# N32MC47x_DP47x register map
Vendor: Nsingtech Ltd.; File version: 1.0
Registers are 32-bit, read-write, reset 0x0 unless marked. A register's access mark holds for its fields unless they carry their own. Offsets are from the block's base; [hi:lo] are bit positions; {n}, {i} and the like mark numbered series; 'fields as' and 'values as' point back to an identical list.

## DAC56
Base 0x4002A800
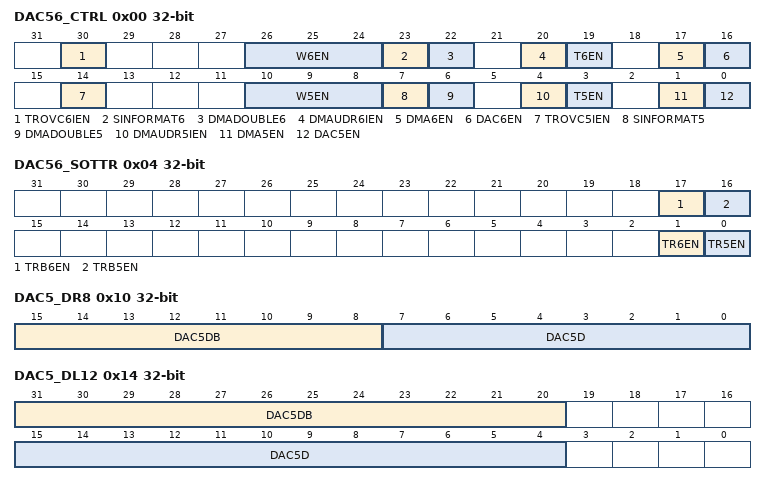
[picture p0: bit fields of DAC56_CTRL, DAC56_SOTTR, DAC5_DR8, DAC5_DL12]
0x00 DAC56_CTRL
  [30] TROVC6IEN, [26:24] W6EN, [23] SINFORMAT6, [22] DMADOUBLE6, [20] DMAUDR6IEN, [19] T6EN, [17] DMA6EN, [16] DAC6EN, [14] TROVC5IEN, [10:8] W5EN, [7] SINFORMAT5, [6] DMADOUBLE5, [4] DMAUDR5IEN, [3] T5EN, [1] DMA5EN, [0] DAC5EN
0x04 DAC56_SOTTR
  [17] TRB6EN, [16] TRB5EN, [1] TR6EN, [0] TR5EN
0x08 DAC5_DATO
  [11:0] DAC5DO
0x0C DAC6_DATO
  [11:0] DAC6DO
0x10 DAC5_DR8
  [15:8] DAC5DB, [7:0] DAC5D
0x14 DAC5_DL12
  [31:20] DAC5DB, [15:4] DAC5D
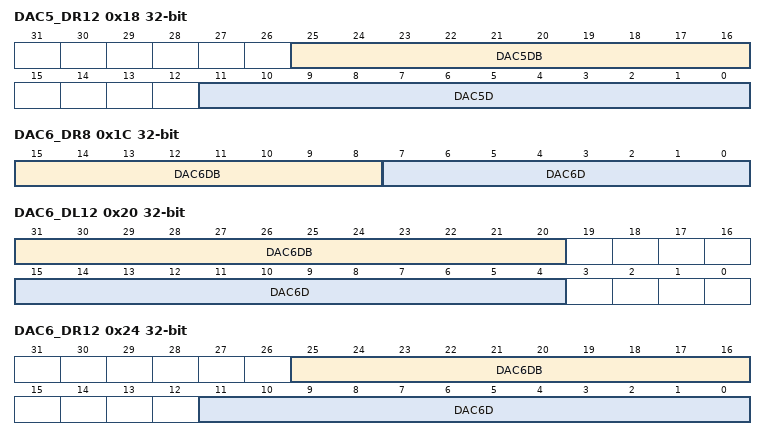
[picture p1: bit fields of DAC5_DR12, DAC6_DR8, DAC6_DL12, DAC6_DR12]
0x18 DAC5_DR12
  [25:16] DAC5DB, [11:0] DAC5D
0x1C DAC6_DR8
  [15:8] DAC6DB, [7:0] DAC6D
0x20 DAC6_DL12
  [31:20] DAC6DB, [15:4] DAC6D
0x24 DAC6_DR12
  [25:16] DAC6DB, [11:0] DAC6D
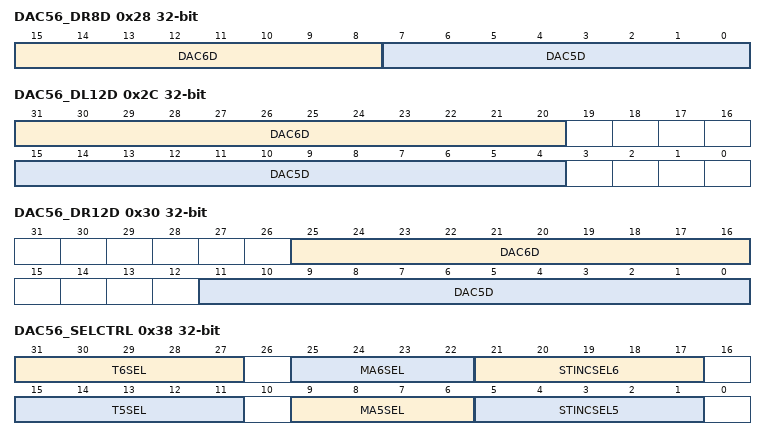
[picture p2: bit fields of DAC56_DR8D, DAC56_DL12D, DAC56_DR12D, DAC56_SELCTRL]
0x28 DAC56_DR8D
  [15:8] DAC6D, [7:0] DAC5D
0x2C DAC56_DL12D
  [31:20] DAC6D, [15:4] DAC5D
0x30 DAC56_DR12D
  [25:16] DAC6D, [11:0] DAC5D
0x38 DAC56_SELCTRL
  [31:27] T6SEL, [25:22] MA6SEL, [21:17] STINCSEL6, [15:11] T5SEL, [9:6] MA5SEL, [5:1] STINCSEL5
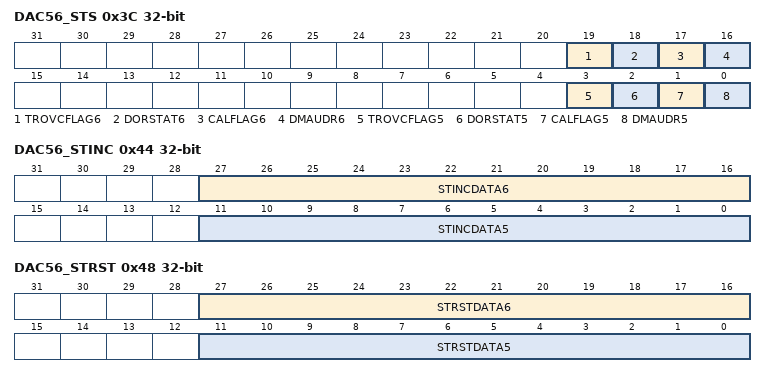
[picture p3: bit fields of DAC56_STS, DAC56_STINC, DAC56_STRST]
0x3C DAC56_STS
  [19] TROVCFLAG6, [18] DORSTAT6, [17] CALFLAG6, [16] DMAUDR6, [3] TROVCFLAG5, [2] DORSTAT5, [1] CALFLAG5, [0] DMAUDR5
0x40 DAC56_GCTRL reset 0x770000
  [20:16] PCS
0x44 DAC56_STINC
  [27:16] STINCDATA6, [11:0] STINCDATA5
0x48 DAC56_STRST
  [27:16] STRSTDATA6, [11:0] STRSTDATA5

## DAC78
Base 0x4002AC00
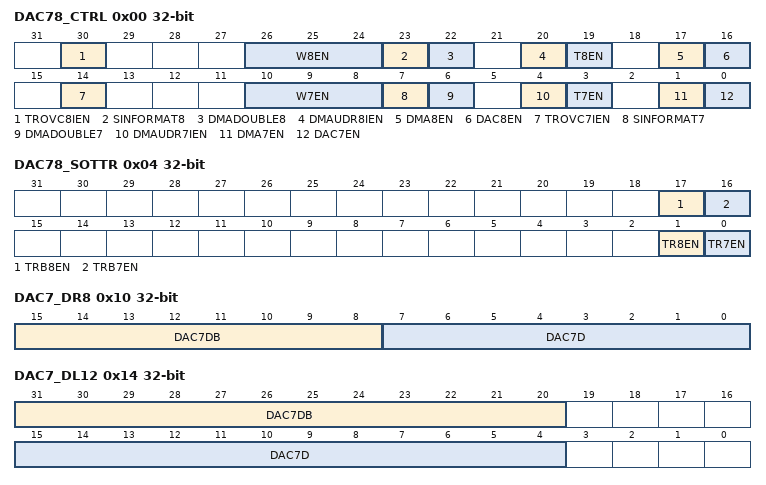
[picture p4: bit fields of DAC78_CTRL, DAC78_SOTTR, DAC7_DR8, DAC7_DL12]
0x00 DAC78_CTRL
  [30] TROVC8IEN, [26:24] W8EN, [23] SINFORMAT8, [22] DMADOUBLE8, [20] DMAUDR8IEN, [19] T8EN, [17] DMA8EN, [16] DAC8EN, [14] TROVC7IEN, [10:8] W7EN, [7] SINFORMAT7, [6] DMADOUBLE7, [4] DMAUDR7IEN, [3] T7EN, [1] DMA7EN, [0] DAC7EN
0x04 DAC78_SOTTR
  [17] TRB8EN, [16] TRB7EN, [1] TR8EN, [0] TR7EN
0x08 DAC7_DATO
  [11:0] DAC7DO
0x0C DAC8_DATO
  [11:0] DAC8DO
0x10 DAC7_DR8
  [15:8] DAC7DB, [7:0] DAC7D
0x14 DAC7_DL12
  [31:20] DAC7DB, [15:4] DAC7D
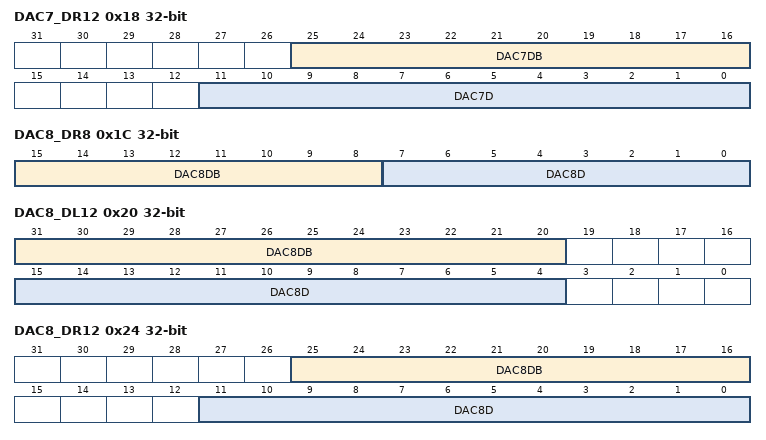
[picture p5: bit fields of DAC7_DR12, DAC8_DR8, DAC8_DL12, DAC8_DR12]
0x18 DAC7_DR12
  [25:16] DAC7DB, [11:0] DAC7D
0x1C DAC8_DR8
  [15:8] DAC8DB, [7:0] DAC8D
0x20 DAC8_DL12
  [31:20] DAC8DB, [15:4] DAC8D
0x24 DAC8_DR12
  [25:16] DAC8DB, [11:0] DAC8D
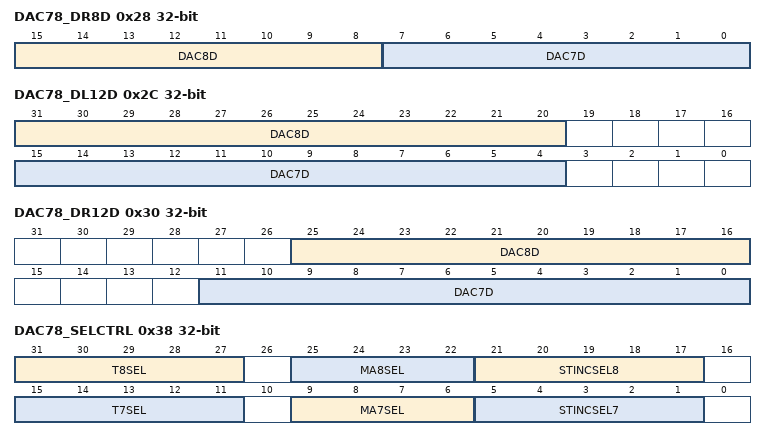
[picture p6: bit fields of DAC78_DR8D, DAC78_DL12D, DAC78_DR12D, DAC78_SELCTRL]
0x28 DAC78_DR8D
  [15:8] DAC8D, [7:0] DAC7D
0x2C DAC78_DL12D
  [31:20] DAC8D, [15:4] DAC7D
0x30 DAC78_DR12D
  [25:16] DAC8D, [11:0] DAC7D
0x38 DAC78_SELCTRL
  [31:27] T8SEL, [25:22] MA8SEL, [21:17] STINCSEL8, [15:11] T7SEL, [9:6] MA7SEL, [5:1] STINCSEL7
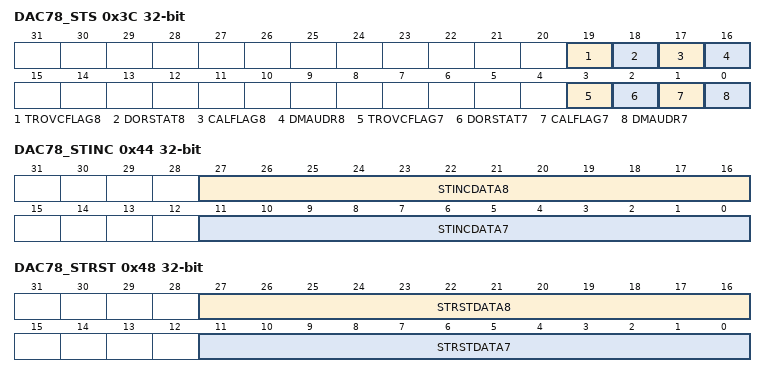
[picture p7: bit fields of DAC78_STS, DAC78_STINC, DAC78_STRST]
0x3C DAC78_STS
  [19] TROVCFLAG8, [18] DORSTAT8, [17] CALFLAG8, [16] DMAUDR8, [3] TROVCFLAG7, [2] DORSTAT7, [1] CALFLAG7, [0] DMAUDR7
0x40 DAC78_GCTRL reset 0x770000
  [20:16] PCS
0x44 DAC78_STINC
  [27:16] STINCDATA8, [11:0] STINCDATA7
0x48 DAC78_STRST
  [27:16] STRSTDATA8, [11:0] STRSTDATA7

## COMP
Base 0x40013800
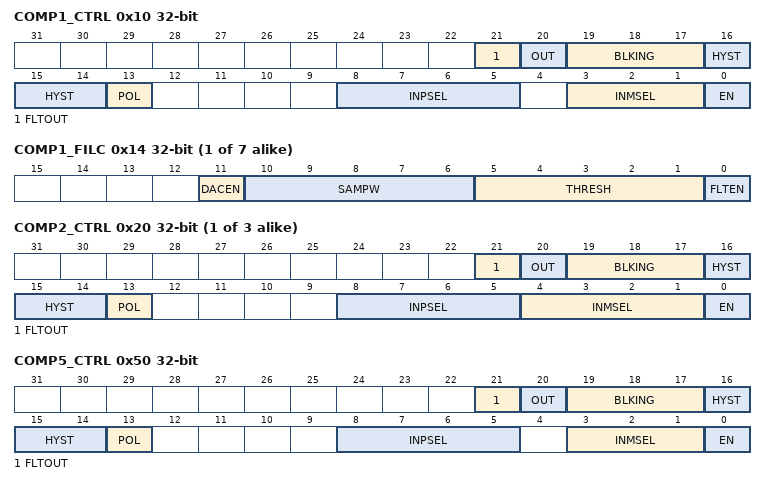
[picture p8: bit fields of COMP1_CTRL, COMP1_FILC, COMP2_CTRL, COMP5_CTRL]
0x10 COMP1_CTRL
  [21] FLTOUT, [20] OUT, [19:17] BLKING, [16:14] HYST, [13] POL, [8:5] INPSEL, [3:1] INMSEL, [0] EN
{0x4+0x10*i} COMP{i}_FILC (i=1..7)
  [11] DACEN, [10:6] SAMPW, [5:1] THRESH, [0] FLTEN
{0x8+0x10*i} COMP{i}_FILP (i=1..7)
  [15:0] CLKPSC
{0x0+0x10*i} COMP{i}_CTRL (i=2..4)
  [21] FLTOUT, [20] OUT, [19:17] BLKING, [16:14] HYST, [13] POL, [8:5] INPSEL, [4:1] INMSEL, [0] EN
0x50 COMP5_CTRL
  fields as COMP1_CTRL
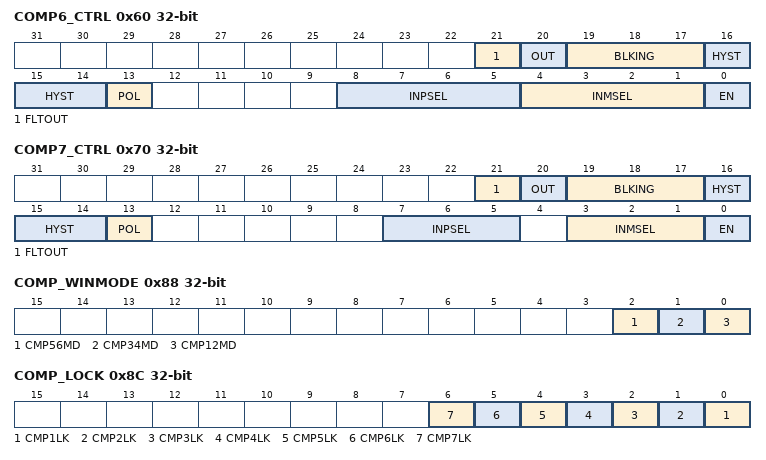
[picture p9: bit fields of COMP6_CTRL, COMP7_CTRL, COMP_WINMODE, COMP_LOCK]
0x60 COMP6_CTRL
  fields as COMP2_CTRL
0x70 COMP7_CTRL
  [21] FLTOUT, [20] OUT, [19:17] BLKING, [16:14] HYST, [13] POL, [7:5] INPSEL, [3:1] INMSEL, [0] EN
0x88 COMP_WINMODE
  [2] CMP56MD, [1] CMP34MD, [0] CMP12MD
0x8C COMP_LOCK
  [n-1] CMP{n}LK (n=1..7)
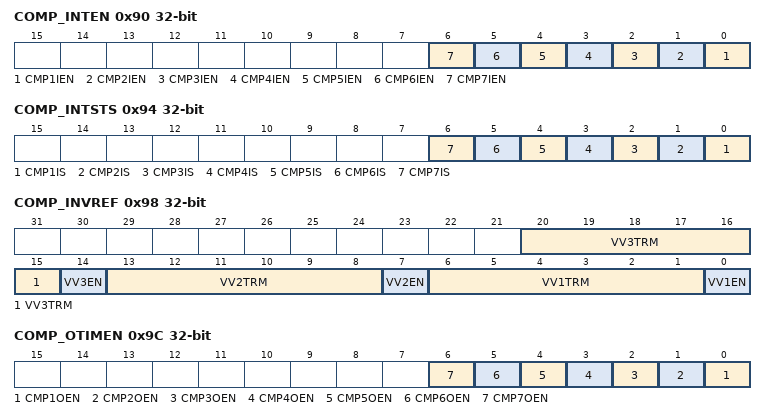
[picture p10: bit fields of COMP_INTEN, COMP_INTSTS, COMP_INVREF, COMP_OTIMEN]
0x90 COMP_INTEN
  [n-1] CMP{n}IEN (n=1..7)
0x94 COMP_INTSTS
  [n-1] CMP{n}IS (n=1..7)
0x98 COMP_INVREF
  [20:15] VV3TRM — VV1TRM
  [14] VV3EN
  [13:8] VV2TRM
  [7] VV2EN
  [6:1] VV1TRM
  [0] VV1EN
0x9C COMP_OTIMEN
  [n-1] CMP{n}OEN (n=1..7)

## PGA
Base 0x40013C00
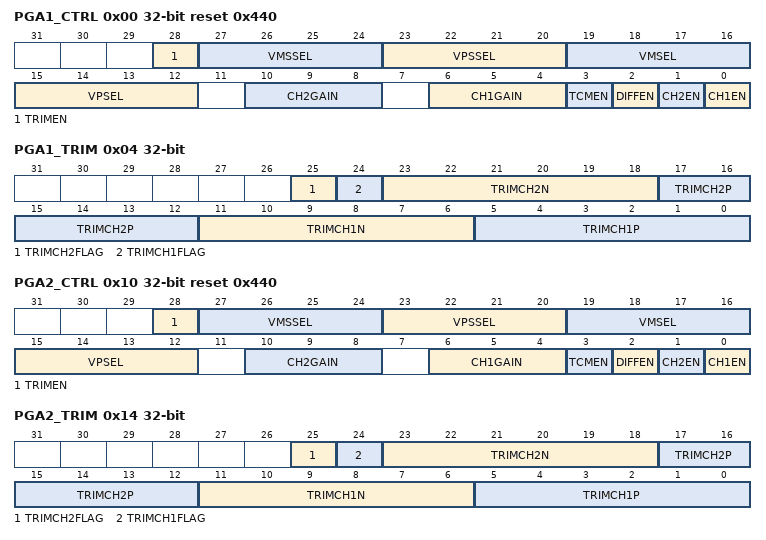
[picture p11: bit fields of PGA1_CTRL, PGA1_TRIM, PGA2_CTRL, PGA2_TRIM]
0x00 PGA1_CTRL reset 0x440
  [28] TRIMEN, [27:24] VMSSEL, [23:20] VPSSEL, [19:16] VMSEL, [15:12] VPSEL, [10:8] CH2GAIN, [6:4] CH1GAIN, [3] TCMEN, [2] DIFFEN, [1] CH2EN, [0] CH1EN
0x04 PGA1_TRIM
  [25] TRIMCH2FLAG, [24] TRIMCH1FLAG, [23:18] TRIMCH2N, [17:12] TRIMCH2P, [11:6] TRIMCH1N, [5:0] TRIMCH1P
0x10 PGA2_CTRL reset 0x440
  fields as PGA1_CTRL
0x14 PGA2_TRIM
  fields as PGA1_TRIM
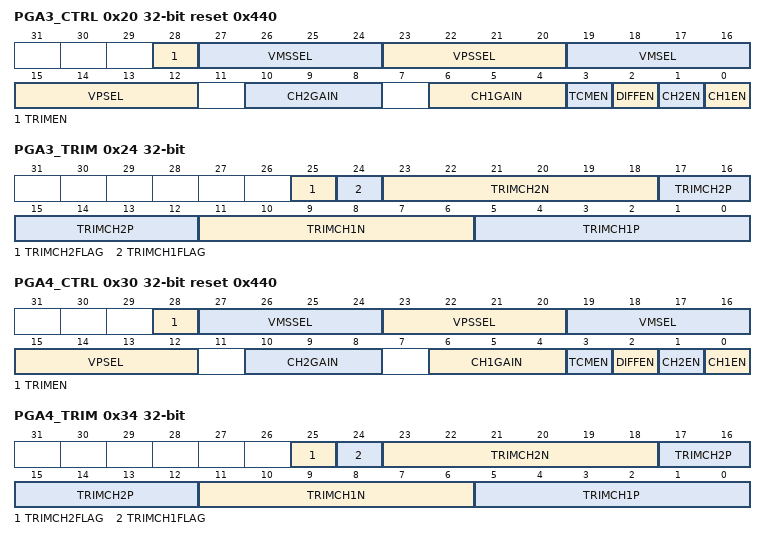
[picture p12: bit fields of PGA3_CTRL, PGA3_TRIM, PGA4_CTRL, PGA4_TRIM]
0x20 PGA3_CTRL reset 0x440
  fields as PGA1_CTRL
0x24 PGA3_TRIM
  fields as PGA1_TRIM
0x30 PGA4_CTRL reset 0x440
  fields as PGA1_CTRL
0x34 PGA4_TRIM
  fields as PGA1_TRIM
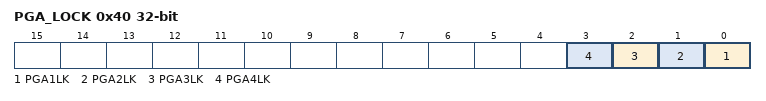
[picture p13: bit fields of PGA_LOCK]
0x40 PGA_LOCK
  [n-1] PGA{n}LK (n=1..4)
0x50 PGA_BIASEN
  [0] IBIASEN
